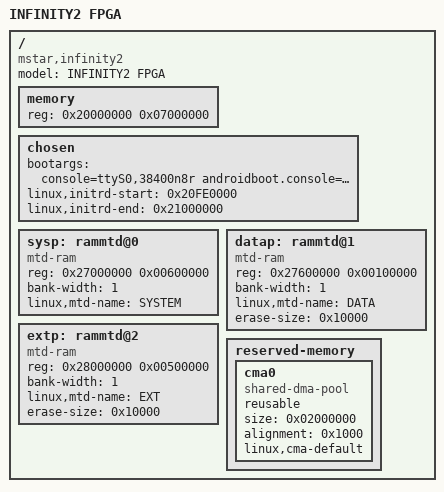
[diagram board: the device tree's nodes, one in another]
/*
 * Copyright (c) 2014 MundoReader S.L.
 * Author: Matthias Brugger <matthias.bgg@gmail.com>
 *
 * This program is free software; you can redistribute it and/or modify
 * it under the terms of the GNU General Public License as published by
 * the Free Software Foundation; either version 2 of the License, or
 * (at your option) any later version.
 *
 * This program is distributed in the hope that it will be useful,
 * but WITHOUT ANY WARRANTY; without even the implied warranty of
 * MERCHANTABILITY or FITNESS FOR A PARTICULAR PURPOSE.  See the
 * GNU General Public License for more details.
 */


/dts-v1/;
#include "infinity2-fpga-CA7.dtsi"

/ {
    model = "INFINITY2 FPGA";
    compatible = "mstar,infinity2";

    memory {
        reg = <0x20000000 0x07000000>;
    };

    chosen {
        bootargs = "console=ttyS0,38400n8r androidboot.console=ttyS0 root=/dev/ram rootwait";
        linux,initrd-start = <0x20FE0000>;
        linux,initrd-end =   <0x21000000>;
    };

    sysp:rammtd@0 {
        compatible = "mtd-ram";
        reg= <0x27000000 0x00600000>;
        bank-width = <1>;
        linux,mtd-name = "SYSTEM";
    };

    /* Size of this partition must be identical to the size of data.jffs2 due to JFFS2 limitation */
    datap:rammtd@1 {
        compatible = "mtd-ram";
        reg= <0x27600000 0x00100000>;
        bank-width = <1>;
        linux,mtd-name = "DATA";
        erase-size = <0x10000>;
    };

    extp:rammtd@2 {
        compatible = "mtd-ram";
        reg= <0x28000000 0x00500000>;
        bank-width = <1>;
        linux,mtd-name = "EXT";
        erase-size = <0x10000>;
    };

/*!!IMPORTANT!! The reserved memory must be 1MB aligned*/
    reserved-memory {
        #address-cells = <1>;
        #size-cells = <1>;
        ranges;

        cma0 {
            compatible = "shared-dma-pool";
            reusable;
            size = <0x02000000>;
            alignment = <0x1000>;
            linux,cma-default;
        };
    };

};
